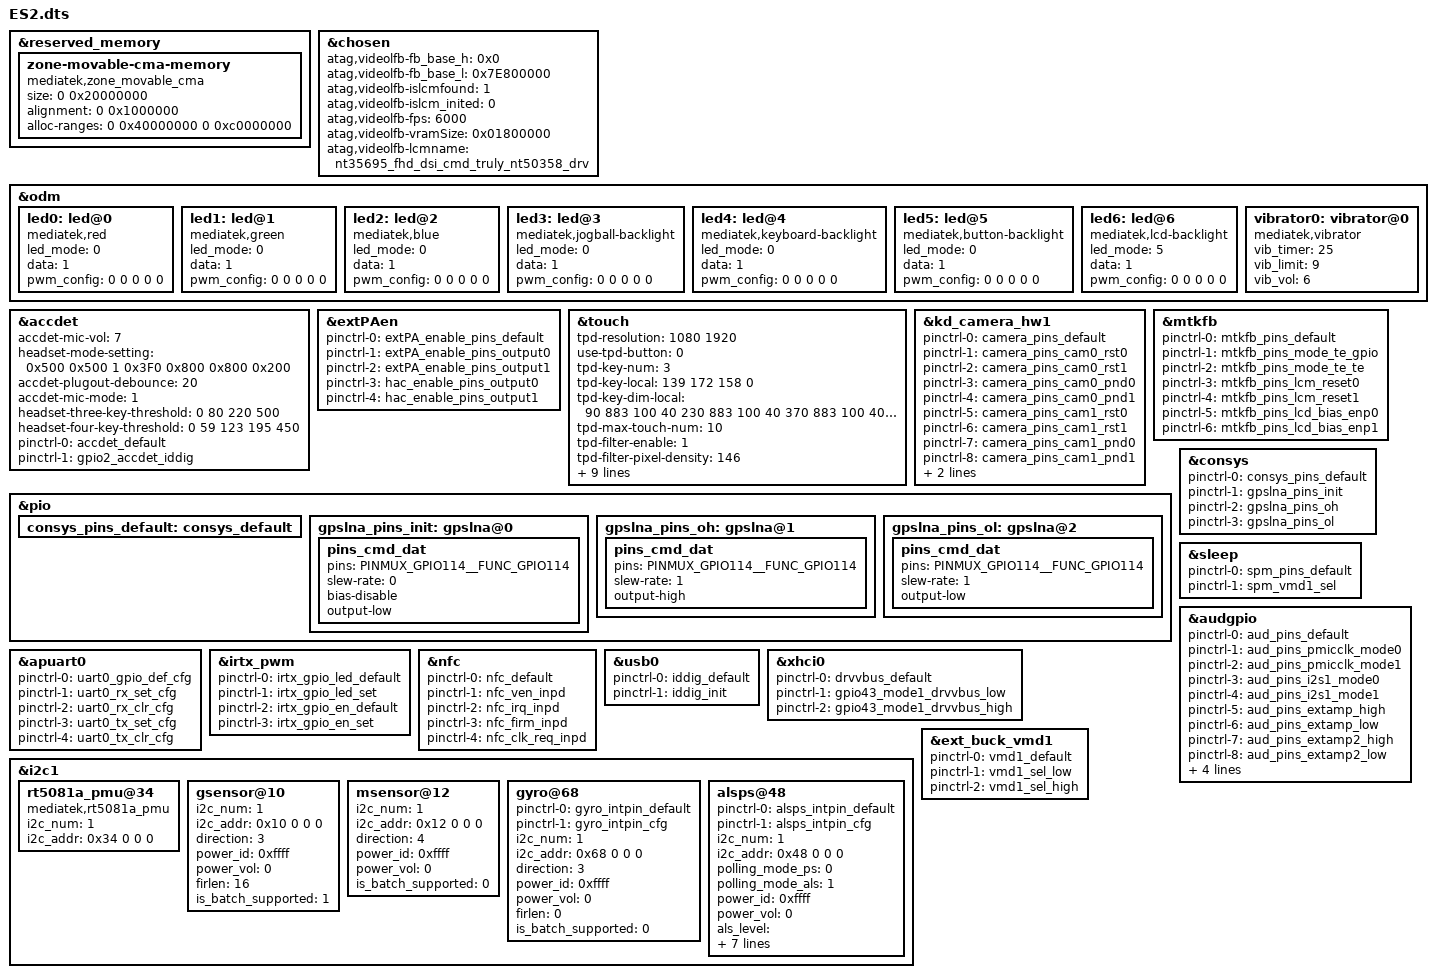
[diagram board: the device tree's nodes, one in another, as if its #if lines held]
#include <generated/autoconf.h>
/dts-v1/;

#ifdef CONFIG_MTK_DTBO_FEATURE
/plugin/;
#include <dt-bindings/mmc/mt6755-msdc.h>
#include "mt6755-pinfunc.h"
#else
#include "mt6755.dts"
#endif

#include "ES2-pinctrl.dts"
&reserved_memory {
	#address-cells = <2>;
	#size-cells = <2>;
	ranges;

	zone-movable-cma-memory {
		compatible = "mediatek,zone_movable_cma";
		size = <0 0x20000000>;
		alignment = <0 0x1000000>;
		alloc-ranges = <0 0x40000000 0 0xc0000000>;
	};

};

/* chosen */
&chosen {
	/* fpga may has no lk, we need to specify display info here */
	/* fb buffer is reserved using this dts by memory node above */
	atag,videolfb-fb_base_h = <0x0>;
	atag,videolfb-fb_base_l = <0x7E800000>;
	atag,videolfb-islcmfound = <1>;
	/* because no lk, so lcm is not inited */
	atag,videolfb-islcm_inited = <0>;
	atag,videolfb-fps= <6000>;
	atag,videolfb-vramSize= <0x01800000>;
	atag,videolfb-lcmname= "nt35695_fhd_dsi_cmd_truly_nt50358_drv";
};

&odm {
	led0:led@0 {
		compatible = "mediatek,red";
		led_mode = <0>;
		data = <1>;
		pwm_config = <0 0 0 0 0>;
	};
	led1:led@1 {
		compatible = "mediatek,green";
		led_mode = <0>;
		data = <1>;
		pwm_config = <0 0 0 0 0>;
	};
	led2:led@2 {
		compatible = "mediatek,blue";
		led_mode = <0>;
		data = <1>;
		pwm_config = <0 0 0 0 0>;
	};
	led3:led@3 {
		compatible = "mediatek,jogball-backlight";
		led_mode = <0>;
		data = <1>;
		pwm_config = <0 0 0 0 0>;
	};
	led4:led@4 {
		compatible = "mediatek,keyboard-backlight";
		led_mode = <0>;
		data = <1>;
		pwm_config = <0 0 0 0 0>;
	};
	led5:led@5 {
		compatible = "mediatek,button-backlight";
		led_mode = <0>;
		data = <1>;
		pwm_config = <0 0 0 0 0>;
	};
	led6:led@6 {
		compatible = "mediatek,lcd-backlight";
		led_mode = <5>;
		data = <1>;
		pwm_config = <0 0 0 0 0>;
	};
	vibrator0:vibrator@0 {
		compatible = "mediatek,vibrator";
		vib_timer = <25>;
		vib_limit = <9>;
		vib_vol= <6>;
	};
};
&accdet {
		accdet-mic-vol = <7>;
		headset-mode-setting = <0x500 0x500 1 0x3F0 0x800 0x800 0x200>;
		accdet-plugout-debounce = <20>;
		/*1:ACC mode, 2:low cost without in bias, 6:low cost with in bias*/
		accdet-mic-mode = <1>;
		/*0--MD_MAX--UP_MAX--DW_MAX*/
		headset-three-key-threshold = <0 80 220 500>;
		/*0--MD_MAX--VOICE_MAX--UP_MAX--DW_MAX*/
		headset-four-key-threshold = <0 59 123 195 450>;
		pinctrl-names = "default", "state_eint_as_int";
		pinctrl-0 = <&accdet_default>;
		pinctrl-1 = <&gpio2_accdet_iddig>;
		status = "okay";
};

&extPAen{
	pinctrl-names = "extPAen_default", "extPAenLow", "extPAenHigh", "hac_low", "hac_high";
	pinctrl-0 = <&extPA_enable_pins_default>;
	pinctrl-1 = <&extPA_enable_pins_output0>;
	pinctrl-2 = <&extPA_enable_pins_output1>;
	pinctrl-3 = <&hac_enable_pins_output0>;
	pinctrl-4 = <&hac_enable_pins_output1>;
	status = "okay";
};
/* ext PA enable end */

/* TOUCH start */
&touch {
	tpd-resolution = <1080 1920>;
	use-tpd-button = <0>;
	tpd-key-num = <3>;
	tpd-key-local= <139 172 158 0>;
	tpd-key-dim-local = <90 883 100 40 230 883 100 40 370 883 100 40 0 0 0 0>;
	tpd-max-touch-num = <10>;
	tpd-filter-enable = <1>;
	tpd-filter-pixel-density = <146>;
	tpd-filter-custom-prameters = <0 0 0 0 0 0 0 0 0 0 0 0>;
	tpd-filter-custom-speed = <0 0 0>;
	pinctrl-names = "default", "state_eint_as_int", "state_eint_output0", "state_eint_output1",
		"state_rst_output0", "state_rst_output1";
	pinctrl-0 = <&ctp_pins_default>;
	pinctrl-1 = <&ctp_pins_eint_as_int>;
	pinctrl-2 = <&ctp_pins_eint_output0>;
	pinctrl-3 = <&ctp_pins_eint_output1>;
	pinctrl-4 = <&ctp_pins_rst_output0>;
	pinctrl-5 = <&ctp_pins_rst_output1>;
	status = "okay";
};
/* TOUCH end */

&kd_camera_hw1 {
	pinctrl-names = "default",
			"cam0_rst0", "cam0_rst1", "cam0_pnd0", "cam0_pnd1",
			"cam1_rst0", "cam1_rst1", "cam1_pnd0", "cam1_pnd1",
			"cam_ldo_sub_vcamd_0", "cam_ldo_sub_vcamd_1";
			/*"cam2_rst0", "cam2_rst1", "cam2_pnd0", "cam2_pnd1",
			"cam_ldo_vcama_0", "cam_ldo_vcama_1";*/
	pinctrl-0 = <&camera_pins_default>;
	pinctrl-1 = <&camera_pins_cam0_rst0>;
	pinctrl-2 = <&camera_pins_cam0_rst1>;
	pinctrl-3 = <&camera_pins_cam0_pnd0>;
	pinctrl-4 = <&camera_pins_cam0_pnd1>;
	pinctrl-5 = <&camera_pins_cam1_rst0>;
	pinctrl-6 = <&camera_pins_cam1_rst1>;
	pinctrl-7 = <&camera_pins_cam1_pnd0>;
	pinctrl-8 = <&camera_pins_cam1_pnd1>;
	pinctrl-9 = <&camera_pins_sub_vcamd0>;
	pinctrl-10 = <&camera_pins_sub_vcamd1>;
	/* for main2 */
	/*pinctrl-9 = <&camera_pins_cam2_rst0>;
	pinctrl-10 = <&camera_pins_cam2_rst1>;
	pinctrl-11 = <&camera_pins_cam2_pnd0>;
	pinctrl-12 = <&camera_pins_cam2_pnd1>;*/
	/* for ldo control by gpio */
	/*pinctrl-13 = <&camera_pins_cam_ldo_vcama_0>;
	pinctrl-14 = <&camera_pins_cam_ldo_vcama_1>;*/
	status = "okay";

};
/* CAMERA GPIO end */

&mtkfb {
	pinctrl-names = "default", "mode_te_gpio", "mode_te_te", "lcm_rst_out0_gpio",
	"lcm_rst_out1_gpio", "lcd_bias_enp0_gpio", "lcd_bias_enp1_gpio";
	pinctrl-0 = <&mtkfb_pins_default>;
	pinctrl-1 = <&mtkfb_pins_mode_te_gpio>;
	pinctrl-2 = <&mtkfb_pins_mode_te_te>;
	pinctrl-3 = <&mtkfb_pins_lcm_reset0>;
	pinctrl-4 = <&mtkfb_pins_lcm_reset1>;
	pinctrl-5 = <&mtkfb_pins_lcd_bias_enp0>;
	pinctrl-6 = <&mtkfb_pins_lcd_bias_enp1>;
	status = "okay";
};/* DISPSYS GPIO standardization end */

/* CONSYS GPIO standardization */
&pio {
        consys_pins_default: consys_default {
        };

        gpslna_pins_init: gpslna@0 {
                pins_cmd_dat {
                        pins = <PINMUX_GPIO114__FUNC_GPIO114>;
                        slew-rate = <0>;
                        bias-disable;
                        output-low;
                };
        };

        gpslna_pins_oh: gpslna@1 {
                pins_cmd_dat {
                        pins = <PINMUX_GPIO114__FUNC_GPIO114>;
                        slew-rate = <1>;
                        output-high;
                };
        };

        gpslna_pins_ol: gpslna@2 {
                pins_cmd_dat {
                        pins = <PINMUX_GPIO114__FUNC_GPIO114>;
                        slew-rate = <1>;
                        output-low;
                };
        };
};

&consys {
	pinctrl-names = "default", "gps_lna_state_init", "gps_lna_state_oh", "gps_lna_state_ol";
	pinctrl-0 = <&consys_pins_default>;
	pinctrl-1 = <&gpslna_pins_init>;
	pinctrl-2 = <&gpslna_pins_oh>;
	pinctrl-3 = <&gpslna_pins_ol>;
	status = "okay";
};
/* CONSYS end */

&sleep{
	pinctrl-names = "default", "vmd1_sel";
	pinctrl-0 = <&spm_pins_default>;
	pinctrl-1 = <&spm_vmd1_sel>;
	status = "okay";
};
/* SPM end */

/* AUDIO GPIO standardization */
&audgpio {
	pinctrl-names = "default", "audpmicclk-mode0", "audpmicclk-mode1",
		"audi2s1-mode0", "audi2s1-mode1", "extamp-pullhigh", "extamp-pulllow",
		"extamp2-pullhigh", "extamp2-pulllow", "rcvspk-pullhigh",
		"rcvspk-pulllow","hpdepop-pullhigh","hpdepop-pulllow";
	pinctrl-0 = <&aud_pins_default>;
	pinctrl-1 = <&aud_pins_pmicclk_mode0>;
	pinctrl-2 = <&aud_pins_pmicclk_mode1>;
	pinctrl-3 = <&aud_pins_i2s1_mode0>;
	pinctrl-4 = <&aud_pins_i2s1_mode1>;
	pinctrl-5 = <&aud_pins_extamp_high>;
	pinctrl-6 = <&aud_pins_extamp_low>;
	pinctrl-7 = <&aud_pins_extamp2_high>;
	pinctrl-8 = <&aud_pins_extamp2_low>;
	pinctrl-9 = <&aud_pins_rcvspk_high>;
	pinctrl-10 = <&aud_pins_rcvspk_low>;
	pinctrl-11 = <&aud_pins_hpdepop_high>;
	pinctrl-12 = <&aud_pins_hpdepop_low>;
	status = "okay";
};

/* AUDIO end */

/* UART GPIO */
&apuart0 {
	pinctrl-names = "uart0_gpio_default",
			"uart0_rx_set",
			"uart0_rx_clear",
			"uart0_tx_set",
			"uart0_tx_clear";
	pinctrl-0 = <&uart0_gpio_def_cfg>;
	pinctrl-1 = <&uart0_rx_set_cfg>;
	pinctrl-2 = <&uart0_rx_clr_cfg>;
	pinctrl-3 = <&uart0_tx_set_cfg>;
	pinctrl-4 = <&uart0_tx_clr_cfg>;
	status = "okay";
};

/* IRTX GPIO end */
&irtx_pwm {
	pinctrl-names = "irtx_gpio_led_default",
			"irtx_gpio_led_set",
			"irtx_gpio_en_default",
			"irtx_gpio_en_set";

	pinctrl-0 = <&irtx_gpio_led_default>;
	pinctrl-1 = <&irtx_gpio_led_set>;
	pinctrl-2 = <&irtx_gpio_en_default>;
	pinctrl-3 = <&irtx_gpio_en_set>;
	status = "okay";
};

/* IRTX GPIO Settings -End */

&nfc {
	/*pinctrl-names = "default", "ven_high", "ven_low", "eint_high", "eint_low", "irq_init";
	pinctrl-0 = <&nfc_default>;
	pinctrl-1 = <&nfc_ven_high>;
	pinctrl-2 = <&nfc_ven_low>;
	pinctrl-5 = <&nfc_eint_high>;
	pinctrl-6 = <&nfc_eint_low>;
	pinctrl-7 = <&nfc_irq_init>;*/
	pinctrl-names = "default", "ven_input_pulldown", "irq_input_pulldown", "firm_input_pulldown", "clk_req_input_pulldown";
	pinctrl-0 = <&nfc_default>;
	pinctrl-1 = <&nfc_ven_inpd>;
	pinctrl-2 = <&nfc_irq_inpd>;
	pinctrl-3 = <&nfc_firm_inpd>;
	pinctrl-4 = <&nfc_clk_req_inpd>;
	status = "okay";
};
/* NFC end */

&usb0 {
	pinctrl-names = "iddig_default", "iddig_init";
	pinctrl-0 = <&iddig_default>;
	pinctrl-1 = <&iddig_init>;
	status = "okay";
};

&xhci0 {
	pinctrl-names = "drvvbus_default", "drvvbus_low", "drvvbus_high";
	pinctrl-0 = <&drvvbus_default>;
	pinctrl-1 = <&gpio43_mode1_drvvbus_low>;
	pinctrl-2 = <&gpio43_mode1_drvvbus_high>;
	status = "okay";
};

&i2c1 {
	rt5081a_pmu@34 {
		compatible = "mediatek,rt5081a_pmu";
		i2c_num	= <1>;
		i2c_addr = <0x34 0 0 0>;
	};

	gsensor@10 {
		i2c_num	= <1>;
		i2c_addr = <0x10 0 0 0>;
		direction = <3>;
		power_id = <0xffff>;
		power_vol = <0>;
		firlen = <16>;
		is_batch_supported = <1>;
	};

	msensor@12 {
		i2c_num = <1>;
		i2c_addr = <0x12 0 0 0>;
		direction = <4>;
		power_id = <0xffff>;
		power_vol = <0>;
		is_batch_supported = <0>;
	};

	gyro@68 {
		pinctrl-names = "pin_default", "pin_cfg";
		pinctrl-0 = <&gyro_intpin_default>;
		pinctrl-1 = <&gyro_intpin_cfg>;
		status = "okay";
		/* customization */
		i2c_num = <1>;
		i2c_addr = <0x68 0 0 0>;
		direction = <3>;
		power_id = <0xffff>;
		power_vol = <0>;
		firlen = <0>;
		is_batch_supported = <0>;
	};

	alsps@48 {
		pinctrl-names = "pin_default", "pin_cfg";
		pinctrl-0 = <&alsps_intpin_default>;
		pinctrl-1 = <&alsps_intpin_cfg>;
		status = "okay";
		i2c_num			= <1>;
		i2c_addr		= <0x48 0 0 0>;
		polling_mode_ps		= <0>;
		polling_mode_als	= <1>;
		power_id		= <0xffff>;
		power_vol		= <0>;
		/* Total has 15 level*/
		als_level	= <0 30 100 200 257 637 1027 2297 5588 6730 11301 20449 25768 31122 45552>;
		/*  Total has 16 range*/
		als_value	= <0 21 48 110 132 304 502 1004 2003 3006 5006 8004 10000 12000 16000 20000>;
		ps_threshold_high	=  <700>;
		ps_threshold_low	=  <300>;
		is_batch_supported_ps	= <1>;
		is_batch_supported_als	= <1>;
	};
};

&ext_buck_vmd1 {
	pinctrl-names = "default", "vmd1_sel_low", "vmd1_sel_high";

	pinctrl-0 = <&vmd1_default>;
	pinctrl-1 = <&vmd1_sel_low>;
	pinctrl-2 = <&vmd1_sel_high>;
};

#include <ES2/cust.dtsi>

#ifdef CONFIG_TOUCHSCREEN_HIMAX_83103
#include "hx83103-touch.dtsi"
#endif

/*End of this file, DO NOT ADD ANYTHING HERE*/

